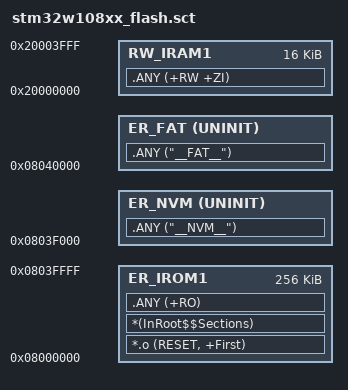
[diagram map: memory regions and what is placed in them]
; *************************************************************
; *** Scatter-Loading Description File generated by uVision ***
; *************************************************************

LR_IROM1 0x08000000 0x00040000  {    ; load region size_region
  ER_IROM1 0x08000000 0x00040000  {  ; load address = execution address
   *.o (RESET, +First)
   *(InRoot$$Sections)
   .ANY (+RO)
  }
  RW_IRAM1 0x20000000 0x00004000  {  ; RW data
   .ANY (+RW +ZI)
  }

    ER_NVM 0x0803F000 UNINIT    {  ; NVM Area
   .ANY ("__NVM__")
  }

    ER_FAT 0x08040000 UNINIT  {   ; FAT Area
   .ANY ("__FAT__")
  }
}

